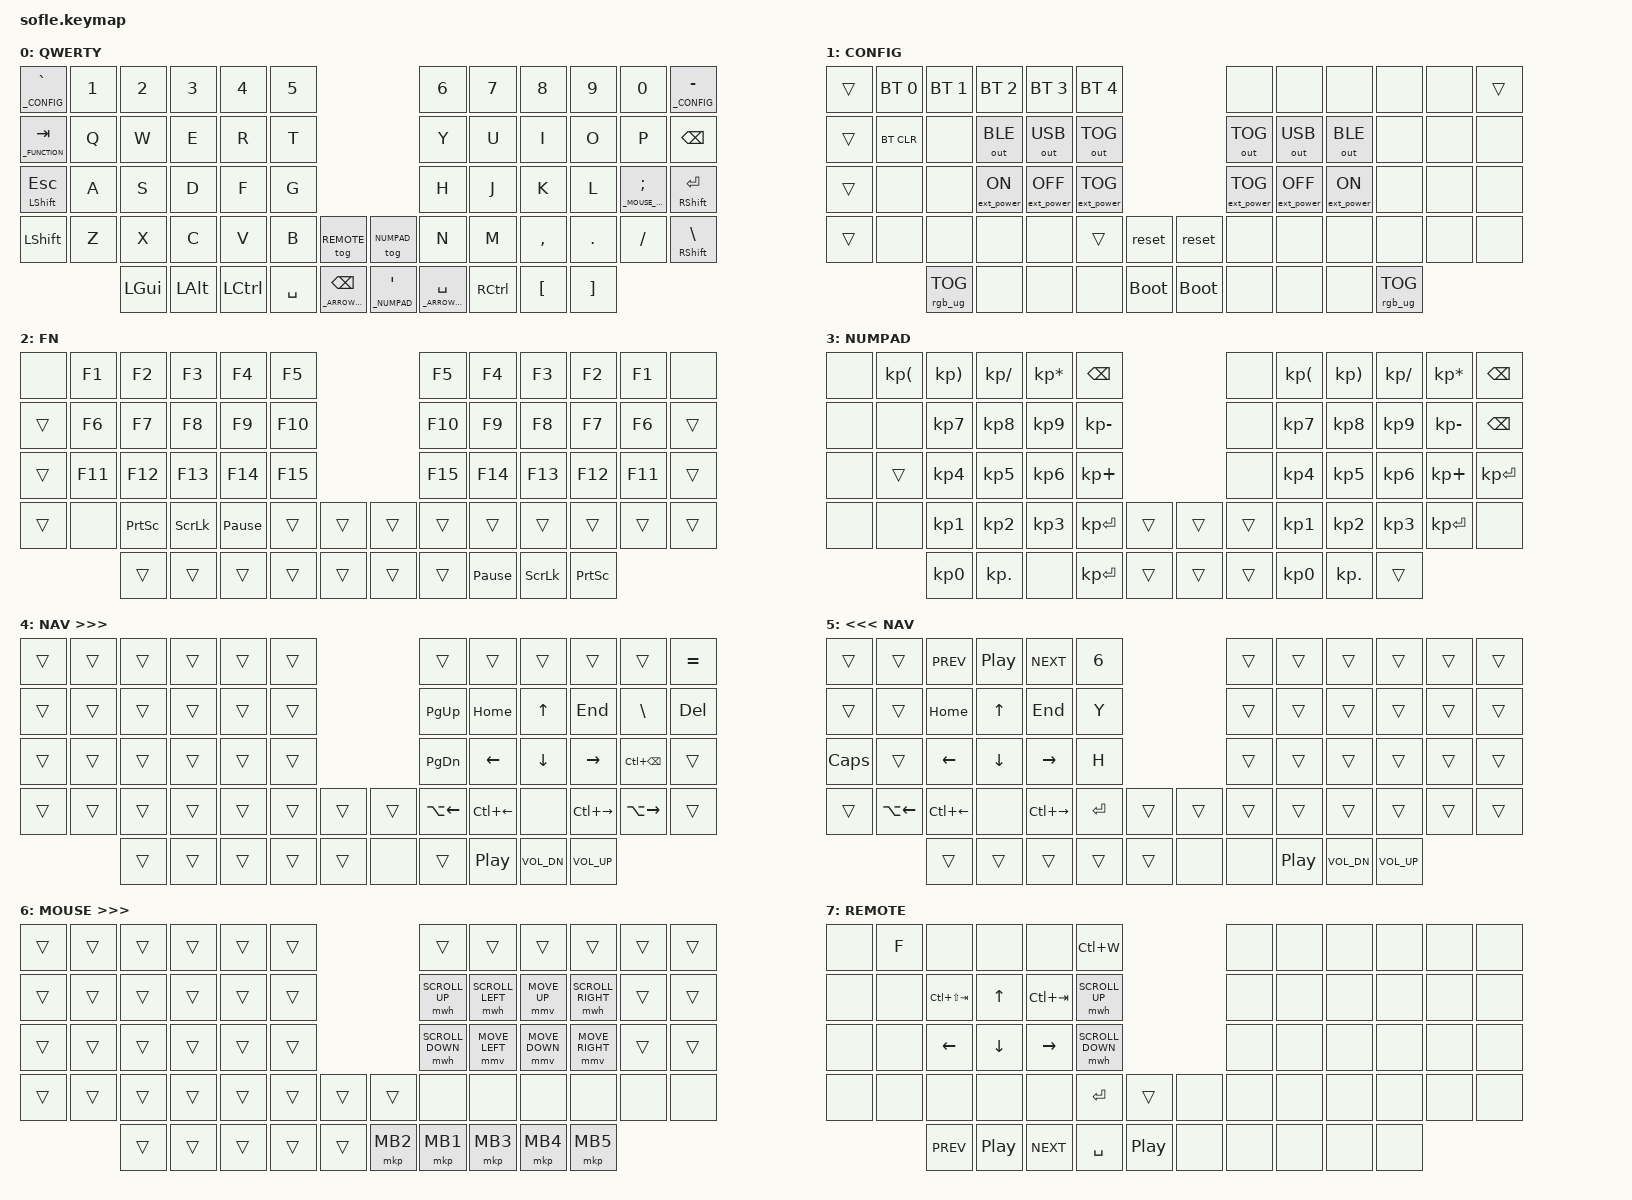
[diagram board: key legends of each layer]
/*
 * Copyright (c) 2020 The ZMK Contributors
 *
 * SPDX-License-Identifier: MIT
 */

#include <behaviors.dtsi>
#include <dt-bindings/zmk/keys.h>
#include <dt-bindings/zmk/bt.h>
#include <dt-bindings/zmk/outputs.h>
#include <dt-bindings/zmk/ext_power.h>
#include <dt-bindings/zmk/rgb.h>
#include <dt-bindings/zmk/mouse.h>


#define _QWERTY         0
#define _CONFIG         1
#define _FUNCTION       2
#define _NUMPAD         3
#define _ARROWS_RIGHT   4
#define _ARROWS_LEFT    5
#define _MOUSE_RIGHT    6
// #define _MOUSE_LEFT     7
// #define _REMOTE         8
#define _REMOTE         7
// #define _QWERTY 0
// #define _QWERTY 0


// TODO: Some binds are waiting for shifted keycode support.
// ------------------------------------------------------------------------------------------------------------
// |       |  F1 |  F2 |  F3  |  F4  |  F5  |                   |  F6  |  F7   |  F8   |  F9  |  F10  |  F11  |
// | `     |   1 |   2 |   3  |   4  |   5  |                   |   6  |   7   |   8   |   9  |    0  |  F12  |
// |       |  !  |  @  |  #   |  $   |  %   |                   |  ^   |  &    |  *    |  (   |   )   |   |   |
// |       |  =  |  -  |  +   |  {   |  }   |        |  |       |  [   |  ]    |  ;    |  :   |   \   |       |
//               |     |      |      |      |        |  |       |      |       |       |      |
&lt {
    quick_tap_ms = <150>;
};

&mmv {
    time-to-max-speed-ms = <450>;
    acceleration-exponent = <1>;
};

&mwh {
    time-to-max-speed-ms = <1000>;
    acceleration-exponent = <1>;
};

#define U_MOUSE_MOVE_MAX 1800
#define U_MOUSE_SCROLL_MAX 160

#undef MOVE_UP
#undef MOVE_DOWN
#undef MOVE_LEFT
#undef MOVE_RIGHT
#define MOVE_UP MOVE_VERT(-U_MOUSE_MOVE_MAX)
#define MOVE_DOWN MOVE_VERT(U_MOUSE_MOVE_MAX)
#define MOVE_LEFT MOVE_HOR(-U_MOUSE_MOVE_MAX)
#define MOVE_RIGHT MOVE_HOR(U_MOUSE_MOVE_MAX)

#undef SCROLL_UP
#undef SCROLL_DOWN
#undef SCROLL_LEFT
#undef SCROLL_RIGHT
#define SCROLL_UP SCROLL_VERT(U_MOUSE_SCROLL_MAX)
#define SCROLL_DOWN SCROLL_VERT(-U_MOUSE_SCROLL_MAX)
#define SCROLL_LEFT SCROLL_HOR(-U_MOUSE_SCROLL_MAX)
#define SCROLL_RIGHT SCROLL_HOR(U_MOUSE_SCROLL_MAX)

/ {
    keymap {
        compatible = "zmk,keymap";

//         _QWERTY {
//             bindings = <
// &lt _CONFIG GRAVE   &kp N1          &kp N2      &kp N3      &kp N4      &kp N5                                                                  &kp N6                  &kp N7      &kp N8              &kp N9              &kp N0                  &lt _CONFIG MINUS
// &lt _FUNCTION TAB   &kp Q           &kp W       &kp E       &kp R       &kp T                                                                   &kp Y                   &kp U       &kp I               &kp O               &kp P                   &kp BSPC
// &mt LEFT_SHIFT ESC  &lt _NUMPAD A   &kp S       &kp D       &kp F       &kp G                                                                   &kp H                   &kp J       &kp K               &kp L               &lt _MOUSE_RIGHT  SEMI  &mt RIGHT_SHIFT ENTER
// &kp LEFT_SHIFT      &kp Z           &kp X       &kp C       &kp V       &kp B       &tog _REMOTE                &tog _NUMPAD                    &kp N                   &kp M       &kp COMMA           &kp DOT             &kp FSLH &kp RIGHT_SHIFT
//                                     &kp LGUI    &kp LALT    &kp LCTRL   &kp SPACE   &lt _ARROWS_LEFT BACKSPACE  &lt _ARROWS_LEFT SINGLE_QUOTE   &lt _ARROWS_RIGHT SPACE &kp RCTRL   &kp LEFT_BRACKET    &kp RIGHT_BRACKET
//             >;

//             sensor-bindings = <&inc_dec_kp C_VOL_UP C_VOL_DN &inc_dec_kp RIGHT LEFT>;
//         };
        _QWERTY {
            label = "QWERTY";
            bindings = <
&lt _CONFIG GRAVE   &kp N1          &kp N2      &kp N3      &kp N4      &kp N5                                                                  &kp N6                  &kp N7      &kp N8              &kp N9              &kp N0                  &lt _CONFIG MINUS
&lt _FUNCTION TAB   &kp Q           &kp W       &kp E       &kp R       &kp T                                                                   &kp Y                   &kp U       &kp I               &kp O               &kp P                   &kp BSPC
&mt LEFT_SHIFT ESC  &kp A           &kp S       &kp D       &kp F       &kp G                                                                   &kp H                   &kp J       &kp K               &kp L               &lt _MOUSE_RIGHT  SEMI  &mt RIGHT_SHIFT ENTER
&kp LEFT_SHIFT      &kp Z           &kp X       &kp C       &kp V       &kp B       &tog _REMOTE                &tog _NUMPAD                    &kp N                   &kp M       &kp COMMA           &kp DOT             &kp FSLH                &mt RIGHT_SHIFT BSLH
                                    &kp LGUI    &kp LALT    &kp LCTRL   &kp SPACE   &lt _ARROWS_LEFT BACKSPACE  &lt _NUMPAD SINGLE_QUOTE        &lt _ARROWS_RIGHT SPACE &kp RCTRL   &kp LEFT_BRACKET    &kp RIGHT_BRACKET
            >;

            sensor-bindings = <&inc_dec_kp C_VOL_UP C_VOL_DN &inc_dec_kp RIGHT LEFT>;
        };


        _CONFIG {
            label = "CONFIG";
            bindings = <
&trans   &bt BT_SEL 0    &bt BT_SEL 1       &bt BT_SEL 2        &bt BT_SEL 3        &bt BT_SEL 4                                        &none               &none               &none               &none               &none   &trans
&trans   &bt BT_CLR      &none              &out OUT_BLE        &out OUT_USB        &out OUT_TOG                                        &out OUT_TOG        &out OUT_USB        &out OUT_BLE        &none               &none   &none
&trans   &none           &none              &ext_power EP_ON    &ext_power EP_OFF   &ext_power EP_TOG                                   &ext_power EP_TOG   &ext_power EP_OFF   &ext_power EP_ON    &none               &none   &none
&trans   &none           &none              &none               &none               &trans              &reset          &reset          &none               &none               &none               &none               &none   &none
                         &rgb_ug RGB_TOG    &none               &none               &none               &bootloader     &bootloader     &none               &none               &none               &rgb_ug RGB_TOG
            >;

            sensor-bindings = <&inc_dec_kp C_VOL_UP C_VOL_DN &inc_dec_kp RIGHT LEFT>;
        };
        
        _FUNCTION {
            label = "FN";
            bindings = <
&none   &kp F1    &kp F2    &kp F3      &kp F4          &kp F5                  &kp F5  &kp F4          &kp F3      &kp F2      &kp F1   &none
&trans  &kp F6    &kp F7    &kp F8      &kp F9          &kp F10                 &kp F10 &kp F9          &kp F8      &kp F7      &kp F6   &trans
&trans  &kp F11   &kp F12   &kp F13     &kp F14         &kp F15                 &kp F15 &kp F14         &kp F13     &kp F12     &kp F11  &trans
&trans  &none     &kp PSCRN &kp SLCK    &kp PAUSE_BREAK &trans  &trans  &trans  &trans  &trans          &trans      &trans      &trans   &trans
                  &trans    &trans      &trans          &trans  &trans  &trans  &trans  &kp PAUSE_BREAK &kp SLCK    &kp PSCRN
            >;
            sensor-bindings = <&inc_dec_kp C_VOL_UP C_VOL_DN &inc_dec_kp RIGHT LEFT>;
        };
        
        _NUMPAD {
            label = "NUMPAD";
            bindings = <
&none       &kp KP_LPAR     &kp KP_RPAR     &kp KP_SLASH    &kp KP_ASTERISK &kp BSPC                        &none     &kp KP_LPAR   &kp KP_RPAR     &kp KP_SLASH  &kp KP_ASTERISK   &kp BSPC
&none       &none           &kp KP_N7       &kp KP_N8       &kp KP_N9       &kp KP_MINUS                    &none     &kp KP_N7     &kp KP_N8       &kp KP_N9     &kp KP_MINUS      &kp BSPC
&none       &trans          &kp KP_N4       &kp KP_N5       &kp KP_N6       &kp KP_PLUS                     &none     &kp KP_N4     &kp KP_N5       &kp KP_N6     &kp KP_PLUS       &kp KP_ENTER
&none       &none           &kp KP_N1       &kp KP_N2       &kp KP_N3       &kp KP_ENTER    &trans   &trans &trans    &kp KP_N1     &kp KP_N2       &kp KP_N3     &kp KP_ENTER      &none
                            &kp KP_N0       &kp KP_DOT      &none           &kp KP_ENTER    &trans   &trans &trans    &kp KP_N0     &kp KP_DOT      &trans
            >;
            sensor-bindings = <&inc_dec_kp C_VOL_UP C_VOL_DN &inc_dec_kp RIGHT LEFT>;
        };
/*
&trans  &trans  &trans  &trans  &trans  &trans                  &trans  &trans  &trans  &trans  &trans  &trans
&trans  &trans  &trans  &trans  &trans  &trans                  &trans  &trans  &trans  &trans  &trans  &trans
&trans  &trans  &trans  &trans  &trans  &trans                  &trans  &trans  &trans  &trans  &trans  &trans
&trans  &trans  &trans  &trans  &trans  &trans  &trans   &trans &trans  &trans  &trans  &trans  &trans  &trans
                &trans  &trans  &trans  &trans  &trans   &trans &trans  &trans  &trans  &trans

&none   &none   &none   &none   &none   &none                   &none   &none   &none   &none   &none   &none
&none   &none   &none   &none   &none   &none                   &none   &none   &none   &none   &none   &none
&none   &none   &none   &none   &none   &none                   &none   &none   &none   &none   &none   &none
&none   &none   &none   &none   &none   &none   &none   &none   &none   &none   &none   &none   &none   &none
                &none   &none   &none   &none   &none   &none   &none   &none   &none   &none
*/        
        _ARROWS_RIGHT {
            label = "NAV >>>";
            bindings = <
&trans  &trans      &trans      &trans      &trans          &trans                  &trans          &trans          &trans          &trans          &trans          &kp EQUAL
&trans  &trans      &trans      &trans      &trans          &trans                  &kp PG_UP       &kp HOME        &kp UP          &kp END         &kp BSLH        &kp DEL
&trans  &trans      &trans      &trans      &trans          &trans                  &kp PG_DN       &kp LEFT        &kp DOWN        &kp RIGHT       &kp LC(BSPC)    &trans
&trans  &trans      &trans      &trans      &trans          &trans  &trans  &trans  &kp LA(LEFT)    &kp LC(LEFT)    &none           &kp LC(RIGHT)   &kp LA(RIGHT)   &trans
                    &trans      &trans      &trans          &trans  &trans  &none   &trans          &kp C_PP        &kp C_VOL_DN    &kp C_VOL_UP
            >;
            sensor-bindings = <&inc_dec_kp C_VOL_UP C_VOL_DN &inc_dec_kp RIGHT LEFT>;
        };
        
        _ARROWS_LEFT {
// TODO: Some binds are waiting for shifted keycode support.
// ------------------------------------------------------------------------------------------------------------
// |       |  F1 |  F2 |  F3  |  F4  |  F5  |                   |  F6  |  F7   |  F8   |  F9  |  F10  |  F11  |
// | `     |   1 |   2 |   3  |   4  |   5  |                   |   6  |   7   |   8   |   9  |    0  |  F12  |
// |       |  !  |  @  |  #   |  $   |  %   |                   |  ^   |  &    |  *    |  (   |   )   |   |   |
// |       |  =  |  -  |  +   |  {   |  }   |        |  |       |  [   |  ]    |  ;    |  :   |   \   |       |
//               |     |      |      |      |        |  |       |      |       |       |      |
            label = "<<< NAV";
            bindings = <
&trans      &trans          &kp C_PREV      &kp C_PP        &kp C_NEXT      &kp N6                          &trans          &trans          &trans          &trans      &trans      &trans
&trans      &trans          &kp HOME        &kp UP          &kp END         &kp Y                           &trans          &trans          &trans          &trans      &trans      &trans
&kp CAPS    &trans          &kp LEFT        &kp DOWN        &kp RIGHT       &kp H                           &trans          &trans          &trans          &trans      &trans      &trans
&trans      &kp LA(LEFT)    &kp LC(LEFT)    &none           &kp LC(RIGHT)   &kp ENTER       &trans  &trans  &trans          &trans          &trans          &trans      &trans      &trans
                            &trans          &trans          &trans          &trans          &trans  &none   &none           &kp C_PP        &kp C_VOL_DN    &kp C_VOL_UP
            >;
            sensor-bindings = <&inc_dec_kp RIGHT LEFT &inc_dec_kp RIGHT LEFT>;
        };
        
        _MOUSE_RIGHT {
            label = "MOUSE >>>";
            bindings = <
&trans  &trans      &trans      &trans      &trans          &trans                          &trans              &trans              &trans          &trans              &trans  &trans
&trans  &trans      &trans      &trans      &trans          &trans                          &mwh SCROLL_UP      &mwh SCROLL_LEFT    &mmv MOVE_UP    &mwh SCROLL_RIGHT   &trans  &trans
&trans  &trans      &trans      &trans      &trans          &trans                          &mwh SCROLL_DOWN    &mmv MOVE_LEFT      &mmv MOVE_DOWN  &mmv MOVE_RIGHT     &trans  &trans
&trans  &trans      &trans      &trans      &trans          &trans  &trans  &trans          &none               &none               &none           &none               &none   &none
                    &trans      &trans      &trans          &trans  &trans  &mkp MB2        &mkp MB1            &mkp MB3            &mkp MB4        &mkp MB5
            >;
            sensor-bindings = <&inc_dec_kp C_VOL_UP C_VOL_DN &inc_dec_kp SCROLL_UP SCROLL_DOWN>;
        };

//         _MOUSE_LEFT {
//             label = "<<< MOUSE";
//             bindings = <
// &trans   &trans   &trans   &trans   &trans   &trans                     &trans   &trans   &trans   &trans   &trans   &trans
// &trans   &trans   &trans   &trans   &trans   &trans                     &trans   &trans   &trans   &trans   &trans   &trans
// &trans   &trans   &trans   &trans   &trans   &trans                     &trans   &trans   &trans   &trans   &trans   &trans
// &trans   &trans   &trans   &trans   &trans   &trans   &trans   &trans   &trans   &trans   &trans   &trans   &trans   &trans
//                   &trans   &trans   &trans   &trans   &trans   &trans   &trans   &trans   &trans   &trans
//             >;
//             sensor-bindings = <&inc_dec_kp C_VOL_UP C_VOL_DN &inc_dec_kp RIGHT LEFT>;
//         };

        _REMOTE {
            label = "REMOTE";
            bindings = <
&none   &kp F   &none               &none               &none       &kp LC(W)                               &none   &none   &none   &none   &none   &none
&none   &none   &kp LC(LS(TAB))     &kp UP              &kp LC(TAB) &mwh SCROLL_UP                          &none   &none   &none   &none   &none   &none
&none   &none   &kp LEFT            &kp DOWN            &kp RIGHT   &mwh SCROLL_DOWN                        &none   &none   &none   &none   &none   &none
&none   &none   &none               &none               &none       &kp ENTER           &trans      &none   &none   &none   &none   &none   &none   &none
                &kp C_PREV          &kp C_PP            &kp C_NEXT  &kp SPACE           &kp C_PP    &none   &none   &none   &none   &none
            >;
            sensor-bindings = <&inc_dec_kp C_VOL_UP C_VOL_DN &inc_dec_kp RIGHT LEFT>;
        };
    };
};
